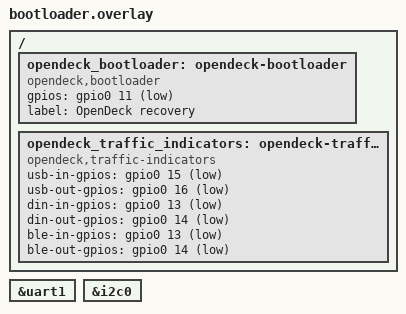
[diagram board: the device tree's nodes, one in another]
opendeck_uart_din_midi: &uart1 {};

opendeck_uart_touchscreen: &uart1 {};

opendeck_i2c_display: &i2c0 {};

/ {
    opendeck_bootloader: opendeck-bootloader {
        compatible = "opendeck,bootloader";
        gpios = <&gpio0 11 (GPIO_PULL_UP | GPIO_ACTIVE_LOW)>;
        label = "OpenDeck recovery";
    };

    opendeck_traffic_indicators: opendeck-traffic-indicators {
        compatible = "opendeck,traffic-indicators";
        usb-in-gpios = <&gpio0 15 GPIO_ACTIVE_LOW>;
        usb-out-gpios = <&gpio0 16 GPIO_ACTIVE_LOW>;
        din-in-gpios = <&gpio0 13 GPIO_ACTIVE_LOW>;
        din-out-gpios = <&gpio0 14 GPIO_ACTIVE_LOW>;
        ble-in-gpios = <&gpio0 13 GPIO_ACTIVE_LOW>;
        ble-out-gpios = <&gpio0 14 GPIO_ACTIVE_LOW>;
    };
};
